AUTOSAR XML (schema 314)
package /ComponentType
  internal behavior Sa_DigMSB_InternalBehavior: component=Sa_DigMSB
    timing event DigMSB_InitEvent: start-on-event=DigMSB_Init, period=0
    timing event TMT_DigMSB_Per2: start-on-event=DigMSB_Per2, period=0.002
    timing event TMT_DigMSB_Per3: start-on-event=DigMSB_Per3, period=0.1
    per instance memory DigMSBEOLData: type=DigMSBEOLType, type-definition=/DataType/DigMSBEOLType
    port-api-options:
      enable-take-address=false, indirect-api=false, port=AlignedCumMechMtrPosCRF
      enable-take-address=false, indirect-api=false, port=AlignedCumMechMtrPosMRF
      enable-take-address=false, indirect-api=false, port=AlignedCumMechMtrPosStatus
      enable-take-address=false, indirect-api=false, port=AssistAssemblyPolarity
      enable-take-address=false, indirect-api=false, port=CorrectedElecMtrPos
      enable-take-address=false, indirect-api=false, port=CumMechMtrPos
      enable-take-address=false, indirect-api=false, port=CumMechMtrPosCRF
      enable-take-address=false, indirect-api=false, port=CumMechMtrPosMRF
      enable-take-address=false, indirect-api=false, port=CumMechMtrPosStatus
      enable-take-address=false, indirect-api=false, port=Die1RxError
      enable-take-address=false, indirect-api=false, port=Die1RxMtrPos
      enable-take-address=false, indirect-api=false, port=Die1RxRevCtr
      enable-take-address=false, indirect-api=false, port=Die1UnderVoltgFltAccum
      enable-take-address=false, indirect-api=false, port=Die2RxError
      enable-take-address=false, indirect-api=false, port=Die2RxMtrPos
      enable-take-address=false, indirect-api=false, port=Die2RxRevCtr
      enable-take-address=false, indirect-api=false, port=EnergyModeState
      enable-take-address=false, indirect-api=false, port=MechMtrPos2
      enable-take-address=false, indirect-api=false, port=MtrPosPolarity
      enable-take-address=false, indirect-api=false, port=NxtrDiagMgr
      enable-take-address=false, indirect-api=false, port=RxMtrPosParityAccum
      enable-take-address=false, indirect-api=false, port=SysCCumMechMtrPosMRF
      enable-take-address=false, indirect-api=false, port=TurnsCounterSelected
      enable-take-address=false, indirect-api=false, port=UncorrMechMtrPos1
    runnable DigMSB_Init
      data read access READ_TurnsCounterSelected_Cnt_lgc: data-element=TurnsCounterSelected.Cnt_lgc
      sync call SC_NxtrDiagMgr_SetNTCStatus: operation=NxtrDiagMgr.SetNTCStatus, timeout=0
    runnable DigMSB_Per2
      13 x data read access:
        READ_AssistAssemblyPolarity_Cnt_s08: data-element=AssistAssemblyPolarity.Cnt_s08
        READ_CorrectedElecMtrPos_Rev_u0p16: data-element=CorrectedElecMtrPos.Rev_u0p16
        READ_CumMechMtrPos_Rev_f32: data-element=CumMechMtrPos.Rev_f32
        READ_Die1RxError_Cnt_u16: data-element=Die1RxError.Cnt_u16
        READ_Die1RxMtrPos_Cnt_u16: data-element=Die1RxMtrPos.Cnt_u16
        READ_Die1RxRevCtr_Cnt_u16: data-element=Die1RxRevCtr.Cnt_u16
        READ_Die1UnderVoltgFltAccum_Cnt_u16: data-element=Die1UnderVoltgFltAccum.Cnt_u16
        READ_Die2RxError_Cnt_u16: data-element=Die2RxError.Cnt_u16
        READ_Die2RxMtrPos_Cnt_u16: data-element=Die2RxMtrPos.Cnt_u16
        READ_Die2RxRevCtr_Cnt_u16: data-element=Die2RxRevCtr.Cnt_u16
        READ_MtrPosPolarity_Cnt_s08: data-element=MtrPosPolarity.Cnt_s08
        READ_RxMtrPosParityAccum_Cnt_u16: data-element=RxMtrPosParityAccum.Cnt_u16
        READ_UncorrMechMtrPos1_Rev_u0p16: data-element=UncorrMechMtrPos1.Rev_u0p16
      8 x data write access:
        WRITE_AlignedCumMechMtrPosCRF_Deg_f32: data-element=AlignedCumMechMtrPosCRF.Deg_f32
        WRITE_AlignedCumMechMtrPosMRF_Deg_f32: data-element=AlignedCumMechMtrPosMRF.Deg_f32
        WRITE_AlignedCumMechMtrPosStatus_Cnt_u08: data-element=AlignedCumMechMtrPosStatus.Cnt_u08
        WRITE_CumMechMtrPosCRF_Deg_f32: data-element=CumMechMtrPosCRF.Deg_f32
        WRITE_CumMechMtrPosMRF_Deg_f32: data-element=CumMechMtrPosMRF.Deg_f32
        WRITE_CumMechMtrPosStatus_Cnt_u08: data-element=CumMechMtrPosStatus.Cnt_u08
        WRITE_MechMtrPos2_Rev_u0p16: data-element=MechMtrPos2.Rev_u0p16
        WRITE_SysCCumMechMtrPosMRF_Deg_f32: data-element=SysCCumMechMtrPosMRF.Deg_f32
      sync call SC_NxtrDiagMgr_GetNTCFailed: operation=NxtrDiagMgr.GetNTCFailed, timeout=0
      sync call SC_NxtrDiagMgr_SetNTCStatus: operation=NxtrDiagMgr.SetNTCStatus, timeout=0
    runnable DigMSB_Per3
      data read access READ_EnergyModeState_Cnt_enum: data-element=EnergyModeState.Cnt_enum
    service-needss:
      swc nv block needs DigMSBEOLBlk: n-data-sets=0, readonly=false, reliability=LOW, resistant-to-changed-sw=false, restore-at-start=false, write-only-once=false, writing-frequency=0, writing-priority=LOW, mirror-block=DigMSBEOLData
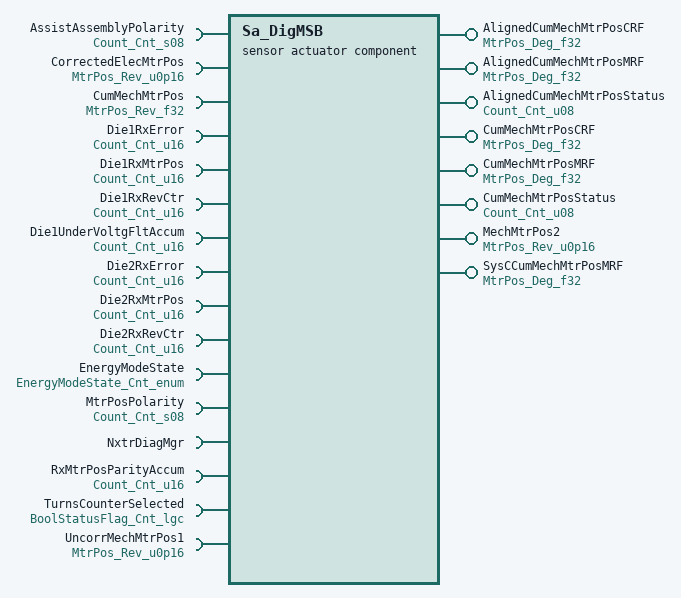
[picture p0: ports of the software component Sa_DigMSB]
  sensor actuator software component type Sa_DigMSB
    8 x provide port:
      AlignedCumMechMtrPosCRF: unqueued-sender-com-spec{data-element=Deg_f32, can-invalidate=false, init-value=D_ZERO_ULS_F32}, provided-interface=MtrPos_Deg_f32
      AlignedCumMechMtrPosMRF: unqueued-sender-com-spec{data-element=Deg_f32, can-invalidate=false, init-value=D_ZERO_ULS_F32}, provided-interface=MtrPos_Deg_f32
      AlignedCumMechMtrPosStatus: unqueued-sender-com-spec{data-element=Cnt_u08, can-invalidate=false, init-value=D_ZERO_CNT_U8}, provided-interface=Count_Cnt_u08
      CumMechMtrPosCRF: unqueued-sender-com-spec{data-element=Deg_f32, can-invalidate=false, init-value=D_ZERO_ULS_F32}, provided-interface=MtrPos_Deg_f32
      CumMechMtrPosMRF: unqueued-sender-com-spec{data-element=Deg_f32, can-invalidate=false, init-value=D_ZERO_ULS_F32}, provided-interface=MtrPos_Deg_f32
      CumMechMtrPosStatus: unqueued-sender-com-spec{data-element=Cnt_u08, can-invalidate=false, init-value=D_ZERO_CNT_U8}, provided-interface=Count_Cnt_u08
      MechMtrPos2: unqueued-sender-com-spec{data-element=Rev_u0p16, can-invalidate=false, init-value=D_ZERO_CNT_U16}, provided-interface=MtrPos_Rev_u0p16
      SysCCumMechMtrPosMRF: unqueued-sender-com-spec{data-element=Deg_f32, can-invalidate=false, init-value=D_ZERO_ULS_F32}, provided-interface=MtrPos_Deg_f32
    16 x require port:
      AssistAssemblyPolarity: unqueued-receiver-com-spec{data-element=Cnt_s08, init-value=D_ZERO_CNT_S8}, required-interface=Count_Cnt_s08
      CorrectedElecMtrPos: unqueued-receiver-com-spec{data-element=Rev_u0p16, init-value=D_ZERO_CNT_U16}, required-interface=MtrPos_Rev_u0p16
      CumMechMtrPos: unqueued-receiver-com-spec{data-element=Rev_f32, init-value=D_ZERO_ULS_F32}, required-interface=MtrPos_Rev_f32
      Die1RxError: unqueued-receiver-com-spec{data-element=Cnt_u16, init-value=D_ZERO_CNT_U16}, required-interface=Count_Cnt_u16
      Die1RxMtrPos: unqueued-receiver-com-spec{data-element=Cnt_u16, init-value=D_ZERO_CNT_U16}, required-interface=Count_Cnt_u16
      Die1RxRevCtr: unqueued-receiver-com-spec{data-element=Cnt_u16, init-value=D_ZERO_CNT_U16}, required-interface=Count_Cnt_u16
      Die1UnderVoltgFltAccum: unqueued-receiver-com-spec{data-element=Cnt_u16, init-value=D_ZERO_CNT_U16}, required-interface=Count_Cnt_u16
      Die2RxError: unqueued-receiver-com-spec{data-element=Cnt_u16, init-value=D_ZERO_CNT_U16}, required-interface=Count_Cnt_u16
      Die2RxMtrPos: unqueued-receiver-com-spec{data-element=Cnt_u16, init-value=D_ZERO_CNT_U16}, required-interface=Count_Cnt_u16
      Die2RxRevCtr: unqueued-receiver-com-spec{data-element=Cnt_u16, init-value=D_ZERO_CNT_U16}, required-interface=Count_Cnt_u16
      EnergyModeState: unqueued-receiver-com-spec{data-element=Cnt_enum, init-value=D_NORMALINIT_CNT_U16}, required-interface=EnergyModeState_Cnt_enum
      MtrPosPolarity: unqueued-receiver-com-spec{data-element=Cnt_s08, init-value=D_ZERO_CNT_S8}, required-interface=Count_Cnt_s08
      NxtrDiagMgr: required-com-specs=[GetNTCActive, GetNTCFailed, GetNTCStatus, SetNTCStatus], required-interface=NxtrDiagMgr
      RxMtrPosParityAccum: unqueued-receiver-com-spec{data-element=Cnt_u16, init-value=D_ZERO_CNT_U16}, required-interface=Count_Cnt_u16
      TurnsCounterSelected: unqueued-receiver-com-spec{data-element=Cnt_lgc, init-value=D_FALSE_CNT_LGC}, required-interface=BoolStatusFlag_Cnt_lgc
      UncorrMechMtrPos1: unqueued-receiver-com-spec{data-element=Rev_u0p16, init-value=D_ZERO_CNT_U16}, required-interface=MtrPos_Rev_u0p16
  swc implementation Sa_DigMSB_Implementation: behavior=Sa_DigMSB_InternalBehavior
    code-descriptors:
      code Code: type=SRC
